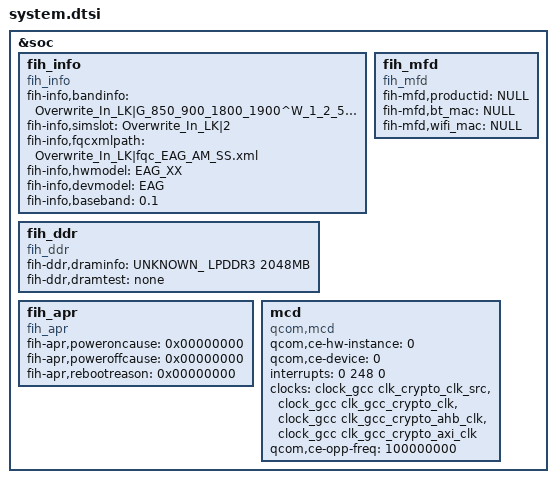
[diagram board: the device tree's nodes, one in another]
&soc {
	fih_info {
		compatible = "fih_info";
		status = "ok";
		fih-info,bandinfo = "Overwrite_In_LK|G_850_900_1800_1900^W_1_2_5_8^C_0^T_34_39^L_1_3_5_7_8_28_38_39_40_41";
		fih-info,simslot  = "Overwrite_In_LK|2";
		fih-info,fqcxmlpath = "Overwrite_In_LK|fqc_EAG_AM_SS.xml";
		fih-info,hwmodel  = "EAG_XX";
		fih-info,devmodel = "EAG";
		fih-info,baseband = "0.1";
	};

	fih_mfd {
		compatible = "fih_mfd";
		status = "ok";
		fih-mfd,productid = "NULL";
		fih-mfd,bt_mac    = "NULL";
		fih-mfd,wifi_mac  = "NULL";
	};

	fih_ddr {
     compatible = "fih_ddr";
     status = "ok";
     fih-ddr,draminfo = "UNKNOWN_ LPDDR3 2048MB";
     fih-ddr,dramtest = "none";
  };

	fih_apr {
		compatible = "fih_apr";
		status = "ok";
		fih-apr,poweroncause = "0x00000000";
		fih-apr,poweroffcause = "0x00000000";
		fih-apr,rebootreason = "0x00000000";
	};

	mcd {
		compatible = "qcom,mcd";
		qcom,ce-hw-instance = <0>;
		qcom,ce-device = <0>;
		interrupts = <0 248 0>;
		interrupt-names = "mcd_irq";
		clocks = <&clock_gcc clk_crypto_clk_src>,
				<&clock_gcc clk_gcc_crypto_clk>,
				<&clock_gcc clk_gcc_crypto_ahb_clk>,
				<&clock_gcc clk_gcc_crypto_axi_clk>;
		clock-names = "core_clk_src", "core_clk",
				"iface_clk", "bus_clk";
		qcom,ce-opp-freq = <100000000>;
	};

};
